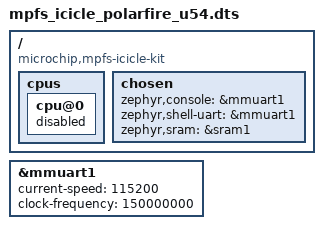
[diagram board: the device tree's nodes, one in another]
/dts-v1/;
#include "mpfs_icicle_common.dtsi"

/ {
	compatible = "microchip,mpfs-icicle-kit", "microchip,mpfs";

	cpus {
		cpu@0 {
			status = "disabled";
		};
	};

	chosen {
		zephyr,console = &mmuart1;
		zephyr,shell-uart = &mmuart1;
		zephyr,sram = &sram1;
	};
};

&mmuart1 {
	status = "okay";
	current-speed = <115200>;
	clock-frequency = <150000000>;
};
